# MCXA156 register map
Vendor: nxp.com; File version: 1.0
CPU: CM33 r2p0, little endian, no MPU, FPU, VTOR, 3 interrupt priority bits
Registers are 32-bit, read-write, reset 0x0 unless marked. A register's access mark holds for its fields unless they carry their own. Offsets are from the block's base; [hi:lo] are bit positions; {n}, {i} and the like mark numbered series.

## FREQME0 — FREQME
Base 0x40009000
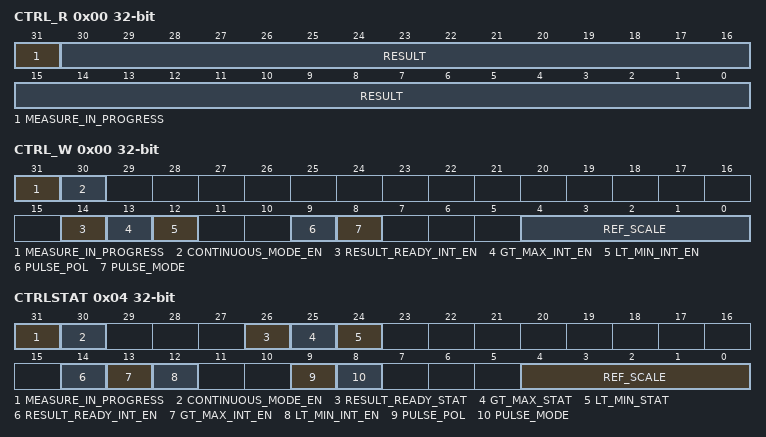
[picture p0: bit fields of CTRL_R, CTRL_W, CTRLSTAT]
0x00 CTRL_R ro (FREQME view) — Control (in Read mode)
  [31] MEASURE_IN_PROGRESS — Measurement In Progress
    0=CYCLE_DONE (Complete); 1=IN_PROGRESS
  [30:0] RESULT — Indicates the measurement result-either the target clock counter value (for Frequency Measurement mode) or pulse width measurement (for Pulse Width Measurement mode)
0x00 CTRL_W wo (FREQME view) — Control (in Write mode)
  [31] MEASURE_IN_PROGRESS — Measurement In Progress
    0=FORCE_TERMINATE (Terminates measurement); 1=INITIATE_A_FREQME_CYCLE (Initiates measurement)
  [30] CONTINUOUS_MODE_EN — Continuous Mode Enable
    0=DISABLE; 1=ENABLE
  [14] RESULT_READY_INT_EN — Result Ready Interrupt Enable
    0=DISABLE; 1=ENABLE
  [13] GT_MAX_INT_EN — Greater Than Maximum Interrupt Enable
    0=DISABLE; 1=ENABLE
  [12] LT_MIN_INT_EN — Less Than Minimum Interrupt Enable
    0=DISABLE; 1=ENABLE
  [9] PULSE_POL — Pulse Polarity
    0=HIGH_PERIOD; 1=LOW_PERIOD
  [8] PULSE_MODE — Pulse Width Measurement Mode Select
    0=FREQ_ME_MODE (Frequency Measurement mode); 1=PULSE_ME_MODE (Pulse Width Measurement mode)
  [4:0] REF_SCALE — Reference Clock Scaling Factor
0x04 CTRLSTAT — Control Status
  [31] MEASURE_IN_PROGRESS ro — Measurement in Progress Status
    0=IDLE (Not in progress); 1=ONGOING (In progress)
  [30] CONTINUOUS_MODE_EN ro — Continuous Mode Enable Status
    0=DISABLED; 1=ENABLED
  [26] RESULT_READY_STAT write-1-clears — Result Ready Status
    0=NOT_COMPLETE; 1=COMPLETE
  [25] GT_MAX_STAT write-1-clears — Greater Than Maximum Result Status
    0=IN_RANGE (Less than MAX[MAX_VALUE]); 1=GT_MAX (Greater than MAX[MAX_VALUE])
  [24] LT_MIN_STAT write-1-clears — Less Than Minimum Results Status
    0=IN_RANGE (Greater than MIN[MIN_VALUE]); 1=LT_MIN (Less than MIN[MIN_VALUE])
  [14] RESULT_READY_INT_EN ro — Result Ready Interrupt Enable
    0=DISABLED; 1=ENABLED
  [13] GT_MAX_INT_EN ro — Greater Than Maximum Interrupt Enable
    0=DISABLED; 1=ENABLED
  [12] LT_MIN_INT_EN ro — Less Than Minimum Interrupt Enable
    0=DISABLED; 1=ENABLED
  [9] PULSE_POL ro — Pulse Polarity
    0=HIGH (High period); 1=LOW (Low period)
  [8] PULSE_MODE ro
    0=FREQ (Frequency Measurement mode); 1=PULSE (Pulse Width Measurement mode)
  [4:0] REF_SCALE ro — Reference Scale
0x08 MIN — Minimum
  [30:0] MIN_VALUE — Minimum Value
0x0C MAX reset 0x7FFFFFFF — Maximum
  [30:0] MAX_VALUE — Maximum Value

## UTICK0 — UTICK
Base 0x4000B000
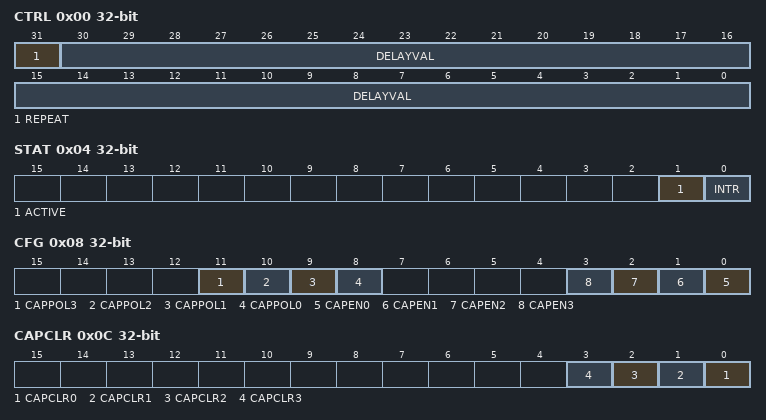
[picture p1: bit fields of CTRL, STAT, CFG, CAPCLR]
0x00 CTRL — Control
  [31] REPEAT — Repeat Delay
    0=DELAYONCE (One-time delay); 1=DELAYREPEATS (Delay repeats continuously)
  [30:0] DELAYVAL — Tick Interval
0x04 STAT write-1-clears — Status
  [1] ACTIVE write-1-clears — Timer Active Flag
    0=TIMERISNOTACTIVE (Inactive (stopped)); 1=TIMERISACTIVE (Active)
  [0] INTR write-1-clears — Interrupt Flag
    0=NOPENDINGINTERRUPT (Not pending); 1=PENDINGINTERRUPT
0x08 CFG — Capture Configuration
  [11] CAPPOL3 — Capture Polarity 3
    0=CAPPOL3POSEDGECAPTURE (Positive); 1=CAPPOL3NEGEDGECAPTURE (Negative)
  [10] CAPPOL2 — Capture Polarity 2
    0=CAPPOL2POSEDGECAPTURE (Positive); 1=CAPPOL2NEGEDGECAPTURE (Negative)
  [9] CAPPOL1 — Capture-Polarity 1
    0=CAPPOL1POSEDGECAPTURE (Positive); 1=CAPPOL1NEGEDGECAPTURE (Negative)
  [8] CAPPOL0 — Capture Polarity 0
    0=CAPPOL0POSEDGECAPTURE (Positive); 1=CAPPOL0NEGEDGECAPTURE (Negative)
  [n] CAPEN{n} (n=0..3) — Enable Capture {n}
    0=CAPEN{n}ISDISABLED (Disable); 1=CAPEN{n}ISENABLED (Enable)
0x0C CAPCLR wo reset not defined — Capture Clear
  [n] CAPCLR{n} (n=0..3) — Clear Capture {n}
    0=CAPCLR{n}NOTHING (Does nothing); 1=CAPCLR{n}CLEARED (Clears the CAP{n} register value)
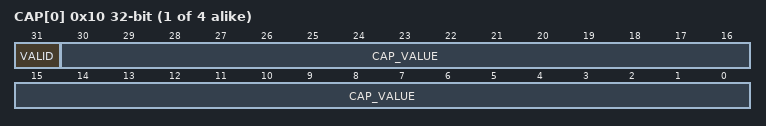
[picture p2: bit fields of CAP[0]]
{0x10+4i} CAP[{i}] (i=0..3) ro — Capture
  [31] VALID — Captured Value Valid Flag
    0=NOTVALID (Valid value not captured); 1=VALID (Valid value captured)
  [30:0] CAP_VALUE — Captured Value for the Related Capture Event
